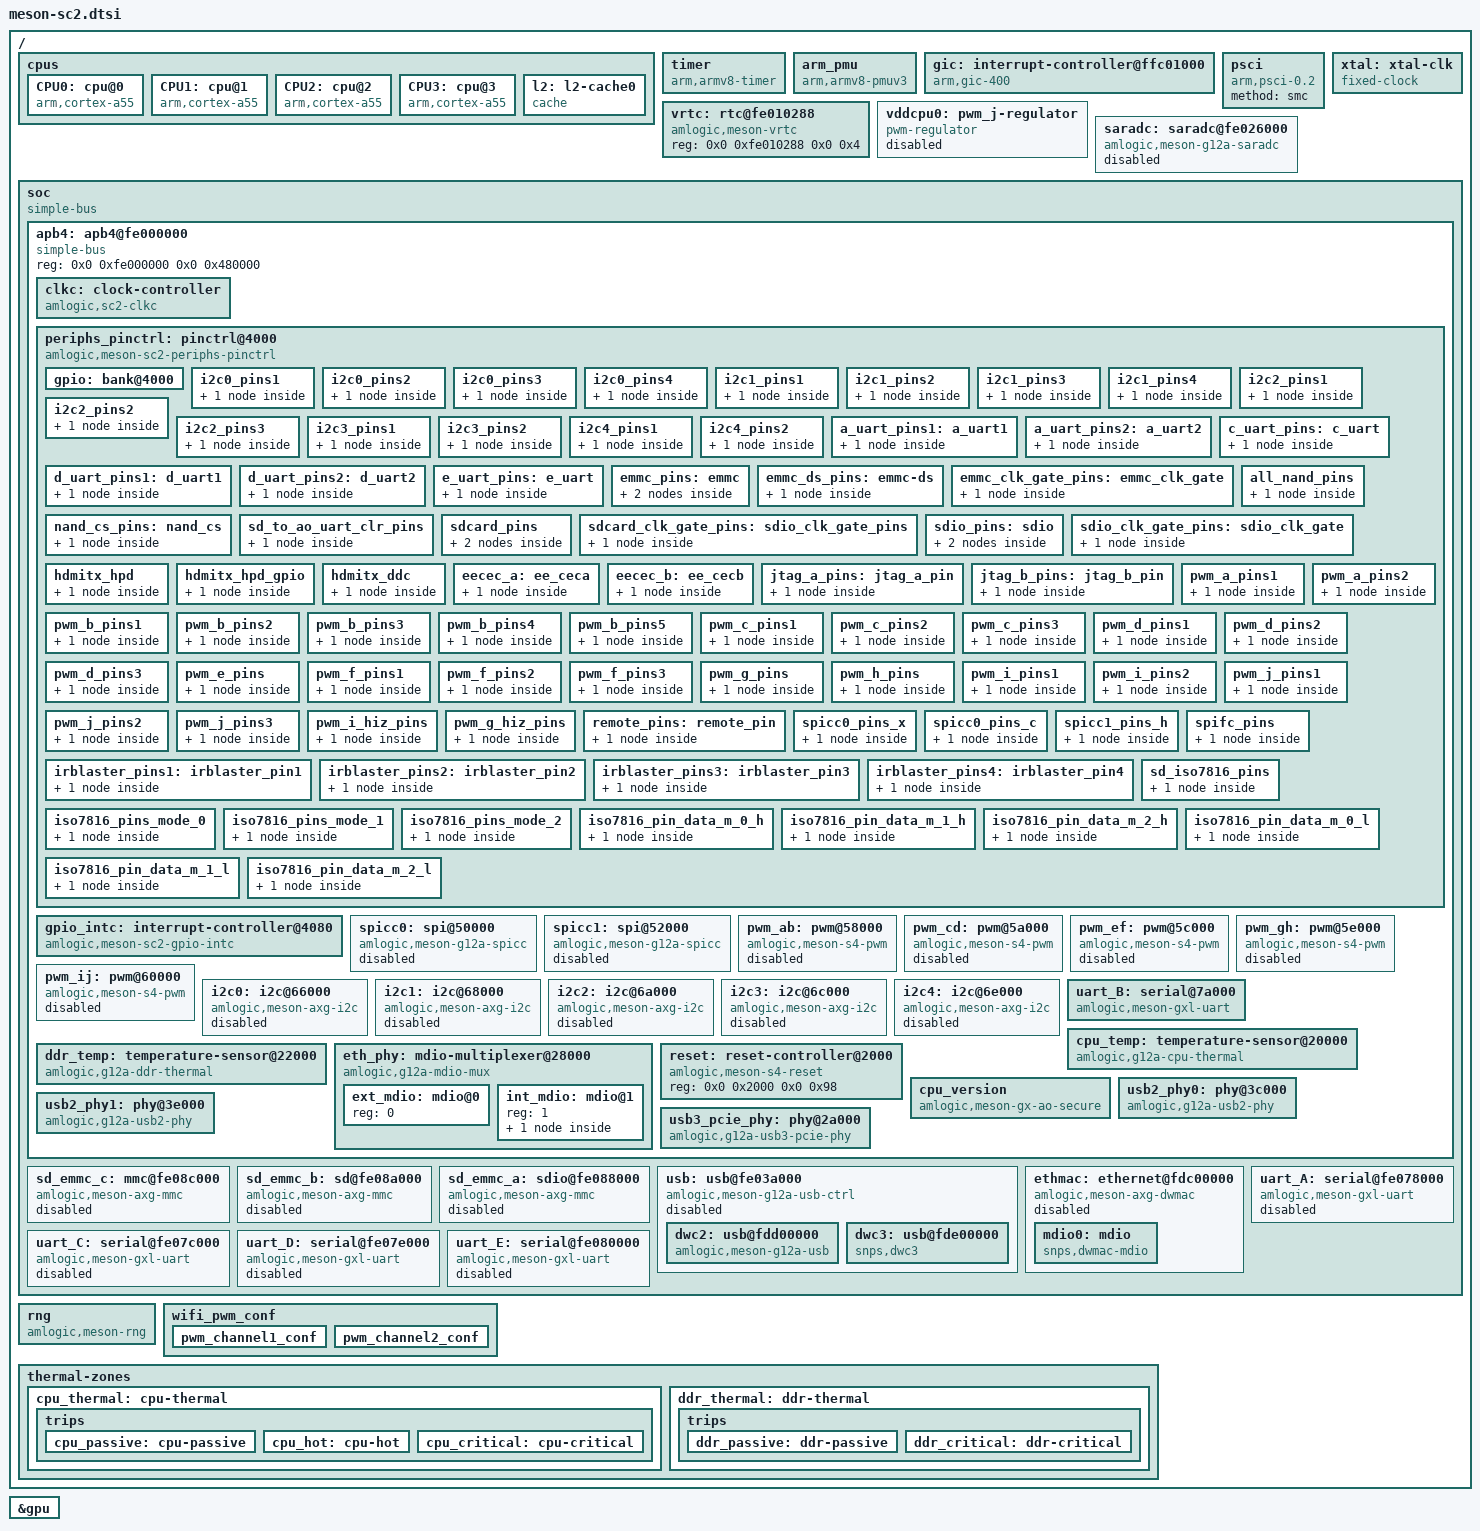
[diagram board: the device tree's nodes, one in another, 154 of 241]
// SPDX-License-Identifier: (GPL-2.0+ OR MIT)
/*
 * Copyright (c) 2019 Amlogic, Inc. All rights reserved.
 */

#include <dt-bindings/phy/phy.h>
#include <dt-bindings/clock/axg-audio-clkc.h>
#include <dt-bindings/clock/amlogic,sc2-clkc.h>
#include <dt-bindings/clock/g12a-aoclkc.h>
#include <dt-bindings/interrupt-controller/irq.h>
#include <dt-bindings/interrupt-controller/arm-gic.h>
#include <dt-bindings/gpio/gpio.h>
#include <dt-bindings/gpio/meson-sc2-gpio.h>
#include <dt-bindings/reset/amlogic,meson-sc2-reset.h>
#include <dt-bindings/pwm/pwm.h>
#include <dt-bindings/pwm/meson.h>
#include <dt-bindings/input/input.h>
// #include <dt-bindings/mailbox/amlogic,mbox.h>
#include "mesong12a-bifrost.dtsi"

/ {
	cpus:cpus {
		#address-cells = <2>;
		#size-cells = <0>;

		CPU0:cpu@0 {
			device_type = "cpu";
			compatible = "arm,cortex-a55";
			reg = <0x0 0x0>;
			enable-method = "psci";
			next-level-cache = <&l2>;
			dynamic-power-coefficient = <230>;
			#cooling-cells = <2>;
			clocks = <&clkc CLKID_CPU_CLK>,
				<&clkc CLKID_CPU_CLK_DYN>,
				<&clkc CLKID_SYS_PLL>,
				<&clkc CLKID_DSU_CLK>,
				<&clkc CLKID_DSU_CLK_FINAL>;
			clock-names = "core_clk",
				"low_freq_clk_parent",
				"high_freq_clk_parent",
				"dsu_clk",
				"dsu_pre_parent";
			operating-points-v2 = <&cpu_opp_table0>;
			cpu-supply = <&vddcpu0>;
			voltage-tolerance = <0>;
			clock-latency = <50000>;
		};

		CPU1:cpu@1 {
			device_type = "cpu";
			compatible = "arm,cortex-a55";
			reg = <0x0 0x1>;
			enable-method = "psci";
			next-level-cache = <&l2>;
			dynamic-power-coefficient = <230>;
			#cooling-cells = <2>;
			clocks = <&clkc CLKID_CPU_CLK>,
				<&clkc CLKID_CPU_CLK_DYN>,
				<&clkc CLKID_SYS_PLL>,
				<&clkc CLKID_DSU_CLK>,
				<&clkc CLKID_DSU_CLK_FINAL>;
			clock-names = "core_clk",
				"low_freq_clk_parent",
				"high_freq_clk_parent",
				"dsu_clk",
				"dsu_pre_parent";
			operating-points-v2 = <&cpu_opp_table0>;
			cpu-supply = <&vddcpu0>;
			voltage-tolerance = <0>;
			clock-latency = <50000>;
		};

		CPU2:cpu@2 {
			device_type = "cpu";
			compatible = "arm,cortex-a55";
			reg = <0x0 0x2>;
			enable-method = "psci";
			next-level-cache = <&l2>;
			dynamic-power-coefficient = <230>;
			#cooling-cells = <2>;
			clocks = <&clkc CLKID_CPU_CLK>,
				<&clkc CLKID_CPU_CLK_DYN>,
				<&clkc CLKID_SYS_PLL>,
				<&clkc CLKID_DSU_CLK>,
				<&clkc CLKID_DSU_CLK_FINAL>;
			clock-names = "core_clk",
				"low_freq_clk_parent",
				"high_freq_clk_parent",
				"dsu_clk",
				"dsu_pre_parent";
			operating-points-v2 = <&cpu_opp_table0>;
			cpu-supply = <&vddcpu0>;
			voltage-tolerance = <0>;
			clock-latency = <50000>;
		};

		CPU3:cpu@3 {
			device_type = "cpu";
			compatible = "arm,cortex-a55";
			reg = <0x0 0x3>;
			enable-method = "psci";
			next-level-cache = <&l2>;
			dynamic-power-coefficient = <230>;
			#cooling-cells = <2>;
			clocks = <&clkc CLKID_CPU_CLK>,
				<&clkc CLKID_CPU_CLK_DYN>,
				<&clkc CLKID_SYS_PLL>,
				<&clkc CLKID_DSU_CLK>,
				<&clkc CLKID_DSU_CLK_FINAL>;
			clock-names = "core_clk",
				"low_freq_clk_parent",
				"high_freq_clk_parent",
				"dsu_clk",
				"dsu_pre_parent";
			operating-points-v2 = <&cpu_opp_table0>;
			cpu-supply = <&vddcpu0>;
			voltage-tolerance = <0>;
			clock-latency = <50000>;
		};

		l2: l2-cache0 {
			compatible = "cache";
		};
	};

	timer {
		compatible = "arm,armv8-timer";
		interrupts = <GIC_PPI 13 (GIC_CPU_MASK_RAW(0xff) | IRQ_TYPE_LEVEL_LOW)>,
			     <GIC_PPI 14 (GIC_CPU_MASK_RAW(0xff) | IRQ_TYPE_LEVEL_LOW)>,
			     <GIC_PPI 11 (GIC_CPU_MASK_RAW(0xff) | IRQ_TYPE_LEVEL_LOW)>,
			     <GIC_PPI 10 (GIC_CPU_MASK_RAW(0xff) | IRQ_TYPE_LEVEL_LOW)>;
	};

	arm_pmu {
		compatible = "arm,armv8-pmuv3";
		private-interrupts;
		/* clusterb-enabled; */
		interrupts = <GIC_SPI 235 IRQ_TYPE_LEVEL_HIGH>,
				<GIC_SPI 236 IRQ_TYPE_LEVEL_HIGH>,
				<GIC_SPI 237 IRQ_TYPE_LEVEL_HIGH>,
				<GIC_SPI 238 IRQ_TYPE_LEVEL_HIGH>;

		reg = <0x0 0xff634680 0x0 0x4>;
		cpumasks = <0xf>;
		/* default 10ms */
		relax-timer-ns = <10000000>;
		/* default 10000us */
		max-wait-cnt = <10000>;
	};

	gic: interrupt-controller@ffc01000 {
		compatible = "arm,gic-400";
		#interrupt-cells = <3>;
		#address-cells = <0>;
		interrupt-controller;
		reg = <0x0 0xfff01000 0 0x1000>,
		      <0x0 0xfff02000 0 0x2000>,
		      <0x0 0xfff04000 0 0x2000>,
		      <0x0 0xfff06000 0 0x2000>;
		interrupts = <GIC_PPI 9 (GIC_CPU_MASK_SIMPLE(8) | IRQ_TYPE_LEVEL_HIGH)>;
	};

	psci {
		compatible = "arm,psci-0.2";
		method = "smc";
	};

	xtal: xtal-clk {
		compatible = "fixed-clock";
		clock-frequency = <24000000>;
		clock-output-names = "xtal";
		#clock-cells = <0>;
	};

	vrtc: rtc@fe010288 {
		compatible = "amlogic,meson-vrtc";
		reg = <0x0 0xfe010288 0x0 0x4>;
		status = "okay";
	};

	vddcpu0: pwm_j-regulator {
		compatible = "pwm-regulator";
		pwms = <&pwm_ij MESON_PWM_1 1500 0>;
		regulator-name = "vddcpu0";
		regulator-min-microvolt = <689000>;
		regulator-max-microvolt = <1049000>;
		regulator-always-on;
		max-duty-cycle = <1500>;
		/* Voltage Duty-Cycle */
		voltage-table = <1049000 0>,
				<1039000 3>,
				<1029000 6>,
				<1019000 9>,
				<1009000 12>,
				<999000 14>,
				<989000 17>,
				<979000 20>,
				<969000 23>,
				<959000 26>,
				<949000 29>,
				<939000 31>,
				<929000 34>,
				<919000 37>,
				<909000 40>,
				<899000 43>,
				<889000 45>,
				<879000 48>,
				<869000 51>,
				<859000 54>,
				<849000 56>,
				<839000 59>,
				<829000 62>,
				<819000 65>,
				<809000 68>,
				<799000 70>,
				<789000 73>,
				<779000 76>,
				<769000 79>,
				<759000 81>,
				<749000 84>,
				<739000 87>,
				<729000 89>,
				<719000 92>,
				<709000 95>,
				<699000 98>,
				<689000 100>;
		status = "disabled";
	};

	saradc: saradc@fe026000 {
		compatible = "amlogic,meson-g12a-saradc",
			   "amlogic,meson-saradc";
		status = "disabled";
		#io-channel-cells = <1>;
		clocks = <&xtal>,
		    <&clkc CLKID_SAR_ADC>,
		    <&clkc CLKID_SARADC_GATE>,
		    <&clkc CLKID_SARADC_MUX>;
		clock-names = "clkin", "core",
		    "adc_clk", "adc_sel";
		interrupts = <GIC_SPI 181 IRQ_TYPE_EDGE_RISING>;
		reg = <0x00 0xfe026000 0x00 0x48>;
	};

	soc {
		compatible = "simple-bus";
		#address-cells = <2>;
		#size-cells = <2>;
		ranges;

		apb4: apb4@fe000000 {
			compatible = "simple-bus";
			reg = <0x0 0xfe000000 0x0 0x480000>;
			#address-cells = <2>;
			#size-cells = <2>;
			ranges = <0x0 0x0 0x0 0xfe000000 0x0 0x480000>;

			clkc: clock-controller {
				compatible = "amlogic,sc2-clkc";
				#clock-cells = <1>;
				reg = <0x0 0x0 0x0 0x49c>,
				      <0x0 0x8000 0x0 0x2e8>,
				      <0x0 0xe140 0x0 0x24>;
				reg-names = "basic", "pll",
					    "cpu_clk";
				clocks = <&xtal>;
				clock-names = "xtal";
				status = "okay";
			};

			periphs_pinctrl: pinctrl@4000 {
				compatible = "amlogic,meson-sc2-periphs-pinctrl";
				#address-cells = <2>;
				#size-cells = <2>;
				ranges;

				gpio: bank@4000 {
					reg = <0x0 0x4000 0x0 0x004c>,
					      <0x0 0x40c0 0x0 0x0220>;
					reg-names = "mux", "gpio";
					gpio-controller;
					#gpio-cells = <2>;
					gpio-ranges = <&periphs_pinctrl 0 0 87>;
				};
			};

			gpio_intc: interrupt-controller@4080 {
				compatible = "amlogic,meson-sc2-gpio-intc",
					     "amlogic,meson-gpio-intc";
				reg = <0x0 0x4080 0x0 0x20>;
				interrupt-controller;
				#interrupt-cells = <2>;
				amlogic,channel-interrupts =
					<10 11 12 13 14 15 16 17 18 19 20 21>;
			};

			spicc0: spi@50000 {
				compatible = "amlogic,meson-g12a-spicc";
				reg = <0x0 0x50000 0x0 0x44>;
				interrupts = <GIC_SPI 183 IRQ_TYPE_LEVEL_HIGH>;
				clocks = <&clkc CLKID_SPICC0>,
					 <&clkc CLKID_SPICC0_GATE>;
				clock-names = "core", "async";
				#address-cells = <1>;
				#size-cells = <0>;
				status = "disabled";
			};

			spicc1: spi@52000 {
				compatible = "amlogic,meson-g12a-spicc";
				reg = <0x0 0x52000 0x0 0x44>;
				interrupts = <GIC_SPI 184 IRQ_TYPE_LEVEL_HIGH>;
				clocks = <&clkc CLKID_SPICC1>,
					 <&clkc CLKID_SPICC1_GATE>;
				clock-names = "core", "async";
				#address-cells = <1>;
				#size-cells = <0>;
				status = "disabled";
			};

			pwm_ab: pwm@58000 {
				compatible = "amlogic,meson-s4-pwm";
				reg = <0x0 0x58000 0x0 0x24>;
				#pwm-cells = <3>;
				clocks = <&clkc CLKID_PWM_A_GATE>,
						<&clkc CLKID_PWM_B_GATE>;
				clock-names = "clkin0", "clkin1";
				status = "disabled";
			};

			pwm_cd: pwm@5a000 {
				compatible = "amlogic,meson-s4-pwm";
				reg = <0x0 0x5a000 0x0 0x24>;
				#pwm-cells = <3>;
				clocks = <&clkc CLKID_PWM_C_GATE>,
						<&clkc CLKID_PWM_D_GATE>;
				clock-names = "clkin0", "clkin1";
				status = "disabled";
			};

			pwm_ef: pwm@5c000 {
				compatible = "amlogic,meson-s4-pwm";
				reg = <0x0 0x5c000 0x0 0x24>;
				#pwm-cells = <3>;
				clocks = <&clkc CLKID_PWM_E_GATE>,
						<&clkc CLKID_PWM_F_GATE>;
				clock-names = "clkin0", "clkin1";
				status = "disabled";
			};

			pwm_gh: pwm@5e000 {
				compatible = "amlogic,meson-s4-pwm";
				reg = <0x0 0x5e000 0x0 0x24>;
				#pwm-cells = <3>;
				clocks = <&clkc CLKID_PWM_G_GATE>,
						<&clkc CLKID_PWM_H_GATE>;
				clock-names = "clkin0", "clkin1";
				status = "disabled";
			};

			pwm_ij: pwm@60000 {
				compatible = "amlogic,meson-s4-pwm";
				reg = <0x0 0x60000 0x0 0x24>;
				#pwm-cells = <3>;
				clocks = <&clkc CLKID_PWM_I_GATE>,
						<&clkc CLKID_PWM_J_GATE>;
				clock-names = "clkin0", "clkin1";
				status = "disabled";
			};

			i2c0: i2c@66000 {
				compatible = "amlogic,meson-axg-i2c";
				reg = <0x0 0x66000 0x0 0x48>;
				interrupts = <GIC_SPI 160 IRQ_TYPE_EDGE_RISING>;
				#address-cells = <1>;
				#size-cells = <0>;
				clocks = <&clkc CLKID_I2C_M_A>;
				status = "disabled";
			};

			i2c1: i2c@68000 {
				compatible = "amlogic,meson-axg-i2c";
				reg = <0x0 0x68000 0x0 0x48>;
				interrupts = <GIC_SPI 161 IRQ_TYPE_EDGE_RISING>;
				#address-cells = <1>;
				#size-cells = <0>;
				clocks = <&clkc CLKID_I2C_M_B>;
				status = "disabled";
			};

			i2c2: i2c@6a000 {
				compatible = "amlogic,meson-axg-i2c";
				reg = <0x0 0x6a000 0x0 0x48>;
				interrupts = <GIC_SPI 162 IRQ_TYPE_EDGE_RISING>;
				#address-cells = <1>;
				#size-cells = <0>;
				clocks = <&clkc CLKID_I2C_M_C>;
				status = "disabled";
			};

			i2c3: i2c@6c000 {
				compatible = "amlogic,meson-axg-i2c";
				reg = <0x0 0x6c000 0x0 0x48>;
				interrupts = <GIC_SPI 163 IRQ_TYPE_EDGE_RISING>;
				#address-cells = <1>;
				#size-cells = <0>;
				clocks = <&clkc CLKID_I2C_M_D>;
				status = "disabled";
			};

			i2c4: i2c@6e000 {
				compatible = "amlogic,meson-axg-i2c";
				reg = <0x0 0x6e000 0x0 0x48>;
				interrupts = <GIC_SPI 164 IRQ_TYPE_EDGE_RISING>;
				#address-cells = <1>;
				#size-cells = <0>;
				clocks = <&clkc CLKID_I2C_M_E>;
				status = "disabled";
			};

			uart_B: serial@7a000 {
				compatible = "amlogic,meson-gxl-uart",
					     "amlogic,meson-ao-uart";
				reg = <0x0 0x7a000 0x0 0x18>;
				interrupts = <GIC_SPI 169 IRQ_TYPE_EDGE_RISING>;
				status = "okay";
				clocks = <&xtal>, <&xtal>, <&xtal>;
				clock-names = "xtal", "pclk", "baud";
			};

			cpu_temp: temperature-sensor@20000 {
				compatible = "amlogic,g12a-cpu-thermal",
					     "amlogic,g12a-thermal";
				reg = <0x0 0x20000 0x0 0x50>, <0x0 0x10328 0x0 0x4>;
				clocks = <&clkc CLKID_TS_CLK_GATE>;
				#thermal-sensor-cells = <0>;
			};

			ddr_temp: temperature-sensor@22000 {
				compatible = "amlogic,g12a-ddr-thermal",
					     "amlogic,g12a-thermal";
				reg = <0x0 0x22000 0x0 0x50>, <0x0 0x10370 0x0 0x4>;
				clocks = <&clkc CLKID_TS_CLK_GATE>;
				#thermal-sensor-cells = <0>;
			};

			eth_phy: mdio-multiplexer@28000 {
				compatible = "amlogic,g12a-mdio-mux";
				reg = <0x0 0x28000 0x0 0xa4>;

				clocks = <&clkc CLKID_ETHPHY>,
					 <&xtal>,
					 <&clkc CLKID_MPLL_50M>;
				clock-names = "pclk", "clkin0", "clkin1";
				mdio-parent-bus = <&mdio0>;
				#address-cells = <1>;
				#size-cells = <0>;

				ext_mdio: mdio@0 {
					reg = <0>;
					#address-cells = <1>;
					#size-cells = <0>;
				};

				int_mdio: mdio@1 {
					reg = <1>;
					#address-cells = <1>;
					#size-cells = <0>;

					internal_ephy: ethernet_phy@8 {
						compatible = "ethernet-phy-id0180.3301",
							     "ethernet-phy-ieee802.3-c22";
						interrupts = <GIC_SPI 75 IRQ_TYPE_LEVEL_HIGH>;
						reg = <8>;
						max-speed = <100>;
					};
				};
			};

			reset: reset-controller@2000 {
				compatible = "amlogic,meson-s4-reset";
				reg = <0x0 0x2000 0x0 0x98>;
				#reset-cells = <1>;
			};

			cpu_version {
				compatible = "amlogic,meson-gx-ao-secure", "syscon";
				reg=<0x0 0x10220 0x0 0x140>;
				amlogic,has-chip-id;
			};

			usb2_phy0: phy@3c000 {
				compatible = "amlogic,g12a-usb2-phy";
				reg = <0x0 0x3c000 0x0 0x2000>;
				clocks = <&xtal>;
				clock-names = "xtal";
				resets = <&reset RESET_USBPHY20>;
				reset-names = "phy";
				#phy-cells = <0>;
			};

			usb2_phy1: phy@3e000 {
				compatible = "amlogic,g12a-usb2-phy";
				reg = <0x0 0x3e000 0x0 0x2000>;
				clocks = <&xtal>;
				clock-names = "xtal";
				resets = <&reset RESET_USBPHY21>;
				reset-names = "phy";
				#phy-cells = <0>;
			};

			usb3_pcie_phy: phy@2a000 {
				compatible = "amlogic,g12a-usb3-pcie-phy";
				reg = <0x0 0x2a000 0x0 0x2000>;
				clocks = <&clkc CLKID_PCIE_PLL>;
				clock-names = "ref_clk";
				resets = <&reset RESET_PCIE_PHY>;
				reset-names = "phy";
				assigned-clocks = <&clkc CLKID_PCIE_PLL>;
				assigned-clock-rates = <100000000>;
				#phy-cells = <1>;
			};
		};

		sd_emmc_c: mmc@fe08c000 {
			compatible = "amlogic,meson-axg-mmc";
			reg = <0x0 0xfe08c000 0x0 0x800>;
			interrupts = <GIC_SPI 178 IRQ_TYPE_EDGE_RISING>;
			status = "disabled";

			clocks = <&clkc CLKID_NAND>,
				 <&clkc CLKID_SD_EMMC_C_CLK>,
				 <&clkc CLKID_FCLK_DIV2>;
			clock-names = "core", "clkin0", "clkin1";
		};

		sd_emmc_b: sd@fe08a000 {
			compatible = "amlogic,meson-axg-mmc";
			reg = <0x0 0xfe08a000 0x0 0x800>;
			interrupts = <GIC_SPI 177 IRQ_TYPE_EDGE_RISING>;
			status = "disabled";
			clocks = <&clkc CLKID_SD_EMMC_B>,
				 <&clkc CLKID_SD_EMMC_B_CLK>,
				 <&clkc CLKID_FCLK_DIV2>;
			clock-names = "core", "clkin0", "clkin1";
		};

		sd_emmc_a: sdio@fe088000 {
			compatible = "amlogic,meson-axg-mmc";
			reg = <0x0 0xfe088000 0x0 0x800>;
			interrupts = <GIC_SPI 176 IRQ_TYPE_LEVEL_HIGH>;
			status = "disabled";
			clocks = <&clkc CLKID_SD_EMMC_A>,
				 <&clkc CLKID_SD_EMMC_A_CLK>,
				 <&clkc CLKID_FCLK_DIV2>;
			clock-names = "core", "clkin0", "clkin1";
			cap-sdio-irq;
			keep-power-in-suspend;
		};

		usb: usb@fe03a000 {
			status = "disabled";
			compatible = "amlogic,meson-g12a-usb-ctrl";
			reg = <0x0 0xfe03a000 0x0 0xa0>;
			interrupts = <GIC_SPI 16 IRQ_TYPE_LEVEL_HIGH>;
			#address-cells = <2>;
			#size-cells = <2>;
			ranges;

			clocks = <&clkc CLKID_USB>;
			resets = <&reset RESET_USBCTRL>;

			dr_mode = "host";

			phys = <&usb2_phy0>, <&usb2_phy1>,
			       <&usb3_pcie_phy PHY_TYPE_USB3>;
			phy-names = "usb2-phy0", "usb2-phy1", "usb3-phy0";

			dwc2: usb@fdd00000 {
				compatible = "amlogic,meson-g12a-usb", "snps,dwc2";
				reg = <0x0 0xfdd00000 0x0 0x100000>;
				interrupts = <GIC_SPI 131 IRQ_TYPE_LEVEL_HIGH>;
				clocks = <&clkc CLKID_USB1_TO_DDR>;
				clock-names = "otg";
				phys = <&usb2_phy1>;
				phy-names = "usb2-phy";
				dr_mode = "peripheral";
				g-rx-fifo-size = <192>;
				g-np-tx-fifo-size = <128>;
				g-tx-fifo-size = <128 128 16 16 16>;
			};

			dwc3: usb@fde00000 {
				compatible = "snps,dwc3";
				reg = <0x0 0xfde00000 0x0 0x100000>;
				interrupts = <GIC_SPI 130 IRQ_TYPE_LEVEL_HIGH>;
				dr_mode = "host";
				snps,dis_u2_susphy_quirk;
				snps,quirk-frame-length-adjustment = <0x20>;
				snps,parkmode-disable-ss-quirk;
			};
		};

		ethmac: ethernet@fdc00000 {
			compatible = "amlogic,meson-axg-dwmac",
				     "snps,dwmac-3.70a",
				     "snps,dwmac";
			reg = <0x0 0xfdc00000 0x0 0x10000>,
			      <0x0 0xfe024000 0x0 0x8>;
			interrupts = <GIC_SPI 74 IRQ_TYPE_LEVEL_HIGH>;
			interrupt-names = "macirq";
			clocks = <&clkc CLKID_ETH>,
				 <&clkc CLKID_FCLK_DIV2>,
				 <&clkc CLKID_MPLL2>;
			clock-names = "stmmaceth", "clkin0", "clkin1";
			rx-fifo-depth = <4096>;
			tx-fifo-depth = <2048>;
			mc_val = <0x4BE0C>;
			status = "disabled";

			mdio0: mdio {
				#address-cells = <1>;
				#size-cells = <0>;
				compatible = "snps,dwmac-mdio";
			};
		};

		uart_A: serial@fe078000 {
			compatible = "amlogic,meson-gxl-uart";
			reg = <0x0 0xfe078000 0x0 0x18>;
			interrupts = <GIC_SPI 168 IRQ_TYPE_EDGE_RISING>;
			status = "disabled";
			clocks = <&xtal>, <&xtal>, <&xtal>;
			clock-names = "xtal", "pclk", "baud";
			pinctrl-names = "default";
			pinctrl-0 = <&a_uart_pins1>;
		};

		uart_C: serial@fe07c000 {
			compatible = "amlogic,meson-gxl-uart";
			reg = <0x0 0xfe07c000 0x0 0x18>;
			interrupts = <GIC_SPI 170 IRQ_TYPE_EDGE_RISING>;
			status = "disabled";
			clocks = <&xtal>, <&xtal>, <&xtal>;
			clock-names = "xtal", "pclk", "baud";
			pinctrl-names = "default";
			pinctrl-0 = <&c_uart_pins>;
		};

		uart_D: serial@fe07e000 {
			compatible = "amlogic,meson-gxl-uart";
			reg = <0x0 0xfe07e000 0x0 0x18>;
			interrupts = <GIC_SPI 171 IRQ_TYPE_EDGE_RISING>;
			status = "disabled";
			clocks = <&xtal>, <&xtal>, <&xtal>;
			clock-names = "xtal", "pclk", "baud";
			pinctrl-names = "default";
			pinctrl-0 = <&d_uart_pins1>;
		};

		uart_E: serial@fe080000 {
			compatible = "amlogic,meson-gxl-uart";
			reg = <0x0 0xfe080000 0x0 0x18>;
			interrupts = <GIC_SPI 172 IRQ_TYPE_EDGE_RISING>;
			status = "disabled";
			clocks = <&xtal>, <&xtal>, <&xtal>;
			clock-names = "xtal", "pclk", "baud";
			pinctrl-names = "default";
			pinctrl-0 = <&e_uart_pins>;
		};
	};

	rng {
		compatible = "amlogic,meson-rng";
		status = "okay";
		#address-cells = <2>;
		#size-cells = <2>;
		reg = <0x0 0xfe440788 0x0 0x0c>;
		quality = /bits/ 16 <1000>;
		version = <2>;
	};

	wifi_pwm_conf:wifi_pwm_conf {
		pwm_channel1_conf {
			pwms = <&pwm_ef 0 30550 0>;
			duty-cycle = <15270>;
			times = <8>;
		};
		pwm_channel2_conf {
			pwms = <&pwm_ef 2 30500 0>;
			duty-cycle = <15250>;
			times = <12>;
		};
	};

	thermal-zones {
		cpu_thermal: cpu-thermal {
			polling-delay = <1000>;
			polling-delay-passive = <100>;
			thermal-sensors = <&cpu_temp>;

			trips {
				cpu_passive: cpu-passive {
					temperature = <85000>; /* millicelsius */
					hysteresis = <2000>; /* millicelsius */
					type = "passive";
				};

				cpu_hot: cpu-hot {
					temperature = <95000>; /* millicelsius */
					hysteresis = <2000>; /* millicelsius */
					type = "hot";
				};

				cpu_critical: cpu-critical {
					temperature = <110000>; /* millicelsius */
					hysteresis = <2000>; /* millicelsius */
					type = "critical";
				};
			};
		};

		ddr_thermal: ddr-thermal {
			polling-delay = <1000>;
			polling-delay-passive = <100>;
			thermal-sensors = <&ddr_temp>;

			trips {
				ddr_passive: ddr-passive {
					temperature = <85000>; /* millicelsius */
					hysteresis = <2000>; /* millicelsius */
					type = "passive";
				};

				ddr_critical: ddr-critical {
					temperature = <110000>; /* millicelsius */
					hysteresis = <2000>; /* millicelsius */
					type = "critical";
				};
			};
		};
	};
};

&periphs_pinctrl {
	i2c0_pins1:i2c0_pins1 {
		mux {
			groups = "i2c0_sda_c",
				"i2c0_scl_c";
			function = "i2c0";
			bias-disable;
		};
	};

	i2c0_pins2:i2c0_pins2 {
		mux {
			groups = "i2c0_sda_h",
				"i2c0_scl_h";
			function = "i2c0";
			bias-disable;
		};
	};

	i2c0_pins3:i2c0_pins3 {
		mux {
			groups = "i2c0_sda_z0",
				"i2c0_scl_z1";
			function = "i2c0";
			bias-disable;
		};
	};

	i2c0_pins4:i2c0_pins4 {
		mux {
			groups = "i2c0_sda_z7",
				"i2c0_scl_z8";
			function = "i2c0";
			bias-disable;

		};
	};

	i2c1_pins1:i2c1_pins1 {
		mux {
			groups = "i2c1_sda_z",
				"i2c1_scl_z";
			function = "i2c1";
			bias-disable;
		};
	};

	i2c1_pins2:i2c1_pins2 {
		mux {
			groups = "i2c1_sda_x",
				"i2c1_scl_x";
			function = "i2c1";
			bias-disable;
		};
	};

	i2c1_pins3:i2c1_pins3 {
		mux {
			groups = "i2c1_sda_h2",
				"i2c1_scl_h3";
			function = "i2c1";
			bias-disable;
		};
	};

	i2c1_pins4:i2c1_pins4 {
		mux {
			groups = "i2c1_sda_h6",
				"i2c1_scl_h7";
			function = "i2c1";
			bias-disable;
		};
	};

	i2c2_pins1:i2c2_pins1 {
		mux {
			groups = "i2c2_sda_x",
				"i2c2_scl_x";
			function = "i2c2";
			bias-disable;
		};
	};

	i2c2_pins2:i2c2_pins2 {
		mux {
			groups = "i2c2_sda_z10",
				"i2c2_scl_z11";
			function = "i2c2";
			bias-disable;
		};
	};

	i2c2_pins3:i2c2_pins3 {
		mux {
			groups = "i2c2_sda_z14",
				"i2c2_scl_z15";
			function = "i2c2";
			bias-disable;
		};
	};

	i2c3_pins1:i2c3_pins1 {
		mux {
			groups = "i2c3_sda_h",
				"i2c3_scl_h";
			function = "i2c3";
			bias-disable;
		};
	};

	i2c3_pins2:i2c3_pins2 {
		mux {
			groups = "i2c3_sda_a",
				"i2c3_scl_a";
			function = "i2c3";
			bias-disable;
		};
	};

	i2c4_pins1:i2c4_pins1 {
		mux {
			groups = "i2c4_sda_d",
				"i2c4_scl_d";
			function = "i2c4";
			bias-disable;
		};
	};

	i2c4_pins2:i2c4_pins2 {
		mux {
			groups = "i2c4_sda_e",
				"i2c4_scl_e";
			function = "i2c4";
			bias-disable;
		};
	};

	a_uart_pins1:a_uart1 {
		mux {
			groups = "uart_a_tx_d2",
				"uart_a_rx_d3";
			function = "uart_a";
		};
	};

	a_uart_pins2:a_uart2 {
		mux {
			groups = "uart_a_tx_d8",
				"uart_a_rx_d9";
			function = "uart_a";
		};
	};

	c_uart_pins:c_uart {
		mux {
			groups = "uart_c_tx",
				"uart_c_rx";
			bias-pull-up;
			output-high;
			function = "uart_c";
		};
	};

	d_uart_pins1:d_uart1 {
		mux {
			groups = "uart_d_tx_x6",
				"uart_d_rx_x7";
			function = "uart_d";
		};
	};

	d_uart_pins2:d_uart2 {
		mux {
			groups = "uart_d_tx_x10",
				"uart_d_rx_x11";
			function = "uart_d";
		};
	};

	e_uart_pins:e_uart {
		mux {
			groups = "uart_e_tx",
				"uart_e_rx",
				"uart_e_cts",
				"uart_e_rts";
			bias-pull-up;
			output-high;
			function = "uart_e";
		};
	};
	emmc_pins: emmc {
		mux-0 {
			groups = "emmc_nand_d0",
				 "emmc_nand_d1",
				 "emmc_nand_d2",
				 "emmc_nand_d3",
				 "emmc_nand_d4",
				 "emmc_nand_d5",
				 "emmc_nand_d6",
				 "emmc_nand_d7",
				 "emmc_cmd";
			function = "emmc";
			bias-pull-up;
		};

		mux-1 {
			groups = "emmc_clk";
			function = "emmc";
			bias-disable;
		};
	};

	emmc_ds_pins: emmc-ds {
		mux {
			groups = "emmc_nand_dqs";
			function = "emmc";
			bias-pull-down;
		};
	};

	emmc_clk_gate_pins: emmc_clk_gate {
		mux {
			groups = "GPIOB_8";
			function = "gpio_periphs";
			bias-pull-down;
		};
	};

	all_nand_pins: all_nand_pins {
	mux {
			groups = "emmc_nand_d0",
				"emmc_nand_d1",
				"emmc_nand_d2",
				"emmc_nand_d3",
				"emmc_nand_d4",
				"emmc_nand_d5",
				"emmc_nand_d6",
				"emmc_nand_d7",
				"nand_ce0",
				"nand_ale",
				"nand_cle",
				"nand_wen_clk",
				"nand_ren_wr";
			function = "nand";
			input-enable;
		};
	};

	nand_cs_pins: nand_cs {
		mux {
			groups = "nand_ce0";
			function = "nand";
		};
	};

	sd_to_ao_uart_clr_pins: sd_to_ao_uart_clr_pins {
		mux {
			groups = "GPIOD_0",
				   "GPIOD_1";
			function = "gpio_periphs";
		};
	};

	sdcard_pins: sdcard_pins {
		mux-0 {
			groups = "sdcard_d0_c",
				 "sdcard_d1_c",
				 "sdcard_d2_c",
				 "sdcard_d3_c",
				 "sdcard_cmd_c";
			function = "sdcard";
			bias-pull-up;
		};

		mux-1 {
			groups = "sdcard_clk_c";
			function = "sdcard";
			bias-pull-up;
		};
	};

	sdcard_clk_gate_pins: sdio_clk_gate_pins {
		mux {
//			groups = "GPIOC_4";
			groups = "sdcard_clk_c";
//			function = "gpio_periphs";
			function = "sdcard";
			bias-pull-down;
		};
	};

	sdio_pins: sdio {
		mux-0 {
			groups = "sdio_d0_x",
				 "sdio_d1_x",
				 "sdio_d2_x",
				 "sdio_d3_x",
				 "sdio_cmd_x";
			function = "sdio";
			bias-pull-up;
		};

		mux-1 {
			groups = "sdio_clk_x";
			function = "sdio";
			bias-disable;
		};
	};

	sdio_clk_gate_pins: sdio_clk_gate {
		mux {
			groups = "GPIOX_4";
			function = "gpio_periphs";
			bias-pull-down;
		};
	};

	hdmitx_hpd: hdmitx_hpd {
		mux {
			groups = "hdmitx_hpd_in";
			function = "hdmitx";
			bias-disable;
		};
	};

	hdmitx_hpd_gpio: hdmitx_hpd_gpio {
		mux {
			groups = "GPIOH_1";
			function = "gpio_periphs";
			bias-disable;
		};
	};

	hdmitx_ddc: hdmitx_ddc {
		mux {
			groups = "hdmitx_sda",
				"hdmitx_sck";
			function = "hdmitx";
			bias-disable;
		};
	};

	eecec_a: ee_ceca {
		mux {
			groups = "cec_a_h";
			function = "cec_a";
		};
	};

	eecec_b: ee_cecb {
		mux {
			groups = "cec_b_h";
			function = "cec_b";
		};
	};

	jtag_a_pins: jtag_a_pin {
		mux {
			groups = "jtag_1_tdi",
				 "jtag_1_tdo",
				 "jtag_1_clk",
				 "jtag_1_tms";
			function = "jtag_1";
		};
	};

	jtag_b_pins: jtag_b_pin {
		mux {
			groups = "jtag_2_tdi",
				 "jtag_2_tdo",
				 "jtag_2_clk",
				 "jtag_2_tms";
			function = "jtag_2";
		};
	};

	pwm_a_pins1: pwm_a_pins1 {
		mux {
			groups = "pwm_a_e";
			function = "pwm_a";
		};
	};

	pwm_a_pins2: pwm_a_pins2 {
		mux {
			groups = "pwm_a_x";
			function = "pwm_a";
		};
	};

	pwm_b_pins1: pwm_b_pins1 {
		mux {
			groups = "pwm_b_h";
			function = "pwm_b";
		};
	};

	pwm_b_pins2: pwm_b_pins2 {
		mux {
			groups = "pwm_b_z0";
			function = "pwm_b";
		};
	};

	pwm_b_pins3: pwm_b_pins3 {
		mux {
			groups = "pwm_b_z13";
			function = "pwm_b";
		};
	};

	pwm_b_pins4: pwm_b_pins4 {
		mux {
			groups = "pwm_b_x7";
			function = "pwm_b";
		};
	};

	pwm_b_pins5: pwm_b_pins5 {
		mux {
			groups = "pwm_b_x19";
			function = "pwm_b";
		};
	};

	pwm_c_pins1: pwm_c_pins1 {
		mux {
			groups = "pwm_c_c";
			function = "pwm_c";
		};
	};

	pwm_c_pins2: pwm_c_pins2 {
		mux {
			groups = "pwm_c_x";
			function = "pwm_c";
		};
	};

	pwm_c_pins3: pwm_c_pins3 {
		mux {
			groups = "pwm_c_z";
			function = "pwm_c";
		};
	};

	pwm_d_pins1: pwm_d_pins1 {
		mux {
			groups = "pwm_d_z";
			function = "pwm_d";
		};
	};

	pwm_d_pins2: pwm_d_pins2 {
		mux {
			groups = "pwm_d_x3";
			function = "pwm_d";
		};
	};

	pwm_d_pins3: pwm_d_pins3 {
		mux {
			groups = "pwm_d_x6";
			function = "pwm_d";
		};
	};

	pwm_e_pins: pwm_e_pins {
		mux {
			groups = "pwm_e";
			function = "pwm_e";
		};
	};

	pwm_f_pins1: pwm_f_pins1 {
		mux {
			groups = "pwm_f_x";
			function = "pwm_f";
		};
	};

	pwm_f_pins2: pwm_f_pins2 {
		mux {
			groups = "pwm_f_h";
			function = "pwm_f";
		};
	};

	pwm_f_pins3: pwm_f_pins3 {
		mux {
			groups = "pwm_f_z";
			function = "pwm_f";
		};
	};

	pwm_g_pins: pwm_g_pins {
		mux {
			groups = "pwm_g";
			function = "pwm_g";
		};
	};

	pwm_h_pins: pwm_h_pins {
		mux {
			groups = "pwm_h";
			function = "pwm_h";
		};
	};

	pwm_i_pins1: pwm_i_pins1 {
		mux {
			groups = "pwm_i_d4";
			function = "pwm_i";
		};
	};

	pwm_i_pins2: pwm_i_pins2 {
		mux {
			groups = "pwm_i_d6";
			function = "pwm_i";
		};
	};

	pwm_j_pins1: pwm_j_pins1 {
		mux {
			groups = "pwm_j_e";
			function = "pwm_j";
		};
	};

	pwm_j_pins2: pwm_j_pins2 {
		mux {
			groups = "pwm_j_d5";
			function = "pwm_j";
		};
	};

	pwm_j_pins3: pwm_j_pins3 {
		mux {
			groups = "pwm_j_d10";
			function = "pwm_j";
		};
	};

	pwm_i_hiz_pins: pwm_i_hiz_pins {
		mux {
			groups = "pwm_i_hiz";
			function = "pwm_i_hiz";
		};
	};

	pwm_g_hiz_pins: pwm_g_hiz_pins {
		mux {
			groups = "pwm_g_hiz";
			function = "pwm_g_hiz";
		};
	};

	remote_pins: remote_pin {
		mux {
			groups = "remote_input_d5";
			function = "remote_input";
			bias-disable;
		};
	};

	spicc0_pins_x: spicc0_pins_x {
		mux {
			groups = "spi_a_mosi_x",
				 "spi_a_miso_x",
				 //"spi_a_ss0_x",
				 "spi_a_sclk_x";
			function = "spi_a";
		};
	};

	spicc0_pins_c: spicc0_pins_c {
		mux {
			groups = "spi_a_mosi_c",
				 "spi_a_miso_c",
				 //"spi_a_ss0_c",
				 "spi_a_sclk_c";
			function = "spi_a";
		};
	};

	spicc1_pins_h: spicc1_pins_h {
		mux {
			groups = "spi_b_mosi_h",
				 "spi_b_miso_h",
				 //"spi_b_ss0_h",
				 "spi_b_sclk_h";
			function = "spi_b";
		};
	};

	spifc_pins:spifc_pins {
		mux {
			groups = "nor_hold",
				 "nor_d",
				 "nor_q",
				 "nor_c",
				 "nor_wp",
				 "nor_cs";
			function = "nor";
		};
	};

	irblaster_pins1:irblaster_pin1 {
		mux {
			groups = "remote_out_h";
			function = "remote_out";
		};
	};

	irblaster_pins2:irblaster_pin2 {
		mux {
			groups = "remote_out_z";
			function = "remote_out";
		};
	};

	irblaster_pins3:irblaster_pin3 {
		mux {
			groups = "remote_out_d4";
			function = "remote_out";
		};
	};

	irblaster_pins4:irblaster_pin4 {
		mux {
			groups = "remote_out_d9";
			function = "remote_out";
		};
	};

	sd_iso7816_pins:sd_iso7816_pins {
		mux {
			groups = "iso7816_clk_c",
				"iso7816_data_c";
			function = "iso7816";
			input-enable;
			bias-pull-down;
		};
	};

	iso7816_pins_mode_0:iso7816_pins_mode_0 {
		mux {
			groups = "iso7816_data_c";
			function = "iso7816";
			input-enable;
			bias-pull-down;
		};
	};

	iso7816_pins_mode_1:iso7816_pins_mode_1 {
		mux {
			groups = "iso7816_data_x";
			function = "iso7816";
			input-enable;
			bias-pull-down;
		};
	};

	iso7816_pins_mode_2:iso7816_pins_mode_2 {
		mux {
			groups = "iso7816_data_h";
			function = "iso7816";
			input-enable;
			bias-pull-down;
		};
	};

	iso7816_pin_data_m_0_h:iso7816_pin_data_m_0_h {
		mux {
			groups = "GPIOC_6";
			function = "gpio_periphs";
			output-high;
			bias-pull-up;
		};
	};

	iso7816_pin_data_m_1_h:iso7816_pin_data_m_1_h {
		mux {
			groups = "GPIOX_9";
			function = "gpio_periphs";
			output-high;
			bias-pull-up;
		};
	};

	iso7816_pin_data_m_2_h:iso7816_pin_data_m_2_h {
		mux {
			groups = "GPIOH_7";
			function = "gpio_periphs";
			output-high;
			bias-pull-up;
		};
	};

	iso7816_pin_data_m_0_l:iso7816_pin_data_m_0_l {
		mux {
			groups = "GPIOC_6";
			function = "gpio_periphs";
			output-low;
			bias-pull-up;
		};
	};

	iso7816_pin_data_m_1_l:iso7816_pin_data_m_1_l {
		mux {
			groups = "GPIOX_9";
			function = "gpio_periphs";
			output-low;
			bias-pull-up;
		};
	};

	iso7816_pin_data_m_2_l:iso7816_pin_data_m_2_l {
		mux {
			groups = "GPIOH_7";
			function = "gpio_periphs";
			output-low;
			bias-pull-up;
		};
	};
};

&gpu{
	reg =   <0 0xFE400000 0 0x04000>, /*mali APB bus base address*/
		<0 0xFE002000 0 0x01000>, /*reset register*/
		<0 0xFF800000 0 0x01000>, /*aobus TODO update*/
		<0 0xFF63c000 0 0x01000>, /*hiubus for clk cntl*/
		<0 0xFE002000 0 0x01000>; /*reset register*/

	interrupts = <GIC_SPI 144 IRQ_TYPE_LEVEL_HIGH>,
		     <GIC_SPI 145 IRQ_TYPE_LEVEL_HIGH>,
		     <GIC_SPI 146 IRQ_TYPE_LEVEL_HIGH>;
	interrupt-names = "gpu", "mmu", "job";

	resets = <&reset RESET_MALI>, <&reset RESET_MALI_APB>;

	clk_cntl_reg = <0x57>;

	clocks = <&clkc CLKID_MALI>;
	clock-names = "gpu_mux";

	/*
	 * Mali clocking is provided by two identical clock paths
	 * MALI_0 and MALI_1 muxed to a single clock by a glitch
	 * free mux to safely change frequency while running.
	 */
	assigned-clocks = <&clkc CLKID_MALI_0_SEL>,
			  <&clkc CLKID_MALI_0>,
			  <&clkc CLKID_MALI>; /* Glitch free mux */
	assigned-clock-parents = <&clkc CLKID_FCLK_DIV2P5>,
				 <0>, /* Do Nothing */
				 <&clkc CLKID_MALI_0>;
	assigned-clock-rates = <0>, /* Do Nothing */
				   <800000000>,
				   <0>; /* Do Nothing */

	tbl =  <&dvfs285_cfg
		&dvfs400_cfg
		&dvfs500_cfg
		&dvfs666_cfg
		&dvfs850_cfg
		&dvfs850_cfg>;
};
